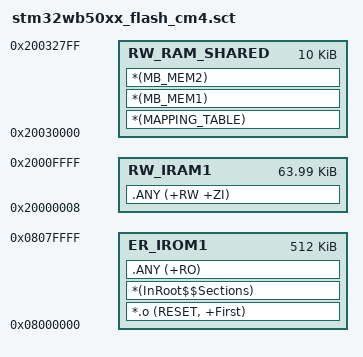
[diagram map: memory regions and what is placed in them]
; *************************************************************
; *** Scatter-Loading Description File generated by uVision ***
; *************************************************************

LR_IROM1 0x08000000 0x00080000  {    ; load region size_region
  ER_IROM1 0x08000000 0x00080000  {  ; load address = execution address
   *.o (RESET, +First)
   *(InRoot$$Sections)
   .ANY (+RO)
  }
  RW_IRAM1     0x20000008 0xFFF8  {  ; RW data
   .ANY (+RW +ZI)
  }
  RW_RAM_SHARED 0x20030000 0x2800  {  ; RW data
   *(MAPPING_TABLE)
   *(MB_MEM1)
   *(MB_MEM2)
  }
  }


